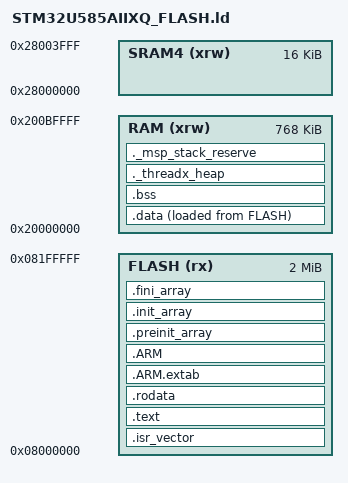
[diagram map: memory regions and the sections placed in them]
/*
******************************************************************************
**
**  File        : LinkerScript.ld
**
**  Author      : STM32CubeIDE
**
**  Abstract    : Linker script for STM32U585xI Device from STM32U5 series
**                      2048Kbytes FLASH
**                      784Kbytes RAM
**
**                Set heap size, stack size and stack location according
**                to application requirements.
**
**                Set memory bank area and size if external memory is used.
**
**  Target      : STMicroelectronics STM32
**
**  Distribution: The file is distributed as is without any warranty
**                of any kind.
**
*****************************************************************************
** @attention
**
** Copyright (c) 2021 STMicroelectronics.
** All rights reserved.
**
** This software is licensed under terms that can be found in the LICENSE file
** in the root directory of this software component.
** If no LICENSE file comes with this software, it is provided AS-IS.
**
*****************************************************************************
*/

/* Entry Point */
ENTRY(Reset_Handler)

/* Highest address of the user mode stack */
_estack = ORIGIN(RAM) + LENGTH(RAM);	/* end of "RAM" Ram type memory */
_sstack = _estack - _Min_Stack_Size;

/* Gallium — keep in sync with APP_* heap sizes in Inc/tx_user.h */
_LIBC_HEAP_SIZE     = 0x18000;	/* 96 KiB: bounded newlib heap (_sbrk) */
_THREADX_HEAP_SIZE  = 0x40000;	/* 256 KiB: CMSIS pools + ThreadX dynamic */
_Min_Stack_Size     = 0x4000;	/* 16 KiB: MSP guard below _estack */

/* Memories definition */
MEMORY
{
  RAM	(xrw)	: ORIGIN = 0x20000000,	LENGTH = 768K
  SRAM4	(xrw)	: ORIGIN = 0x28000000,	LENGTH = 16K
  FLASH	(rx)	: ORIGIN = 0x08000000,	LENGTH = 2048K
}

/* Sections */
SECTIONS
{
  /* The startup code into "FLASH" Rom type memory */
  .isr_vector :
  {
    KEEP(*(.isr_vector)) /* Startup code */
  } >FLASH

  /* The program code and other data into "FLASH" Rom type memory */
  .text :
  {
    *(.text)           /* .text sections (code) */
    *(.text*)          /* .text* sections (code) */
    *(.glue_7)         /* glue arm to thumb code */
    *(.glue_7t)        /* glue thumb to arm code */
    *(.eh_frame)

    KEEP (*(.init))
    KEEP (*(.fini))

    _etext = .;        /* define a global symbols at end of code */
  } >FLASH

  /* Constant data into "FLASH" Rom type memory */
  .rodata :
  {
    *(.rodata)         /* .rodata sections (constants, strings, etc.) */
    *(.rodata*)        /* .rodata* sections (constants, strings, etc.) */
  } >FLASH

  .ARM.extab (READONLY) : /* The READONLY keyword is only supported in GCC11 and later, remove it if using GCC10 or earlier. */
  {
    *(.ARM.extab* .gnu.linkonce.armextab.*)
  } >FLASH

  .ARM (READONLY) : /* The READONLY keyword is only supported in GCC11 and later, remove it if using GCC10 or earlier. */
  {
    __exidx_start = .;
    *(.ARM.exidx*)
    __exidx_end = .;
  } >FLASH

  .preinit_array (READONLY) : /* The READONLY keyword is only supported in GCC11 and later, remove it if using GCC10 or earlier. */
  {
    PROVIDE_HIDDEN (__preinit_array_start = .);
    KEEP (*(.preinit_array*))
    PROVIDE_HIDDEN (__preinit_array_end = .);
  } >FLASH

  .init_array (READONLY) : /* The READONLY keyword is only supported in GCC11 and later, remove it if using GCC10 or earlier. */
  {
    PROVIDE_HIDDEN (__init_array_start = .);
    KEEP (*(SORT(.init_array.*)))
    KEEP (*(.init_array*))
    PROVIDE_HIDDEN (__init_array_end = .);
  } >FLASH

  .fini_array (READONLY) : /* The READONLY keyword is only supported in GCC11 and later, remove it if using GCC10 or earlier. */
  {
    PROVIDE_HIDDEN (__fini_array_start = .);
    KEEP (*(SORT(.fini_array.*)))
    KEEP (*(.fini_array*))
    PROVIDE_HIDDEN (__fini_array_end = .);
  } >FLASH

  /* Used by the startup to initialize data */
  _sidata = LOADADDR(.data);

  /* Initialized data sections into "RAM" Ram type memory */
  .data :
  {
    _sdata = .;        /* create a global symbol at data start */
    *(.data)           /* .data sections */
    *(.data*)          /* .data* sections */
    *(.RamFunc)        /* .RamFunc sections */
    *(.RamFunc*)       /* .RamFunc* sections */

    _edata = .;        /* define a global symbol at data end */
  } >RAM AT> FLASH

  /* Uninitialized data section into "RAM" Ram type memory */
  .bss :
  {
    /* This is used by the startup in order to initialize the .bss section */
    _sbss = .;         /* define a global symbol at bss start */
    __bss_start__ = _sbss;
    *(.bss)
    *(.bss*)
    *(COMMON)

    _ebss = .;         /* define a global symbol at bss end */
    __bss_end__ = _ebss;
  } >RAM

  /* Gallium */
  /* Bounded libc heap: [_Heap_Begin, _Heap_Limit) — must not overlap ThreadX */
  . = ALIGN(8);
  PROVIDE ( end = . );
  PROVIDE ( _end = . );
  PROVIDE ( _Heap_Begin = . );
  . = . + _LIBC_HEAP_SIZE;
  PROVIDE ( _Heap_Limit = . );

  ._threadx_heap :
  {
    . = ALIGN(8);
    PROVIDE ( __RAM_segment_used_end__ = . );
    . = . + _THREADX_HEAP_SIZE;
    . = ALIGN(8);
  } >RAM AT> RAM

  /* MSP reserve at top of RAM (link-time overflow check; see _estack / _Min_Stack_Size) */
  ._msp_stack_reserve :
  {
    . = . + _Min_Stack_Size;
    . = ALIGN(8);
  } >RAM

  /* Remove information from the compiler libraries */
  /DISCARD/ :
  {
    libc.a ( * )
    libm.a ( * )
    libgcc.a ( * )
  }

  .ARM.attributes 0 : { *(.ARM.attributes) }
}
